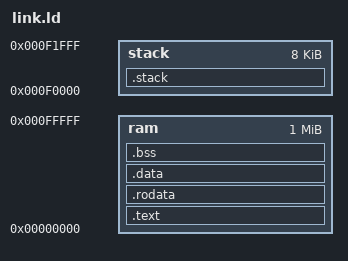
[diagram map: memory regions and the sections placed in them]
/* Copyright lowRISC contributors.
   Licensed under the Apache License, Version 2.0, see LICENSE for details.
   SPDX-License-Identifier: Apache-2.0 */

OUTPUT_ARCH(riscv)

MEMORY
{
    ram         : ORIGIN = 0x00000000, LENGTH = 0x100000 /* 1MB */
    stack       : ORIGIN = 0x000F0000, LENGTH = 0x2000  /* 32 kB */
}

/* Stack information variables */
_min_stack      = 0x2000;   /* 8K - minimum stack space to reserve */
_stack_len     = LENGTH(stack);
_stack_start   = ORIGIN(stack) + LENGTH(stack);

ENTRY(_start)


SECTIONS
{
    .text : {
        . = ALIGN(4);
        *(.text)
        *(.text.*)
    }  > ram

    .rodata : {
        . = ALIGN(4);
        /* Small RO data before large RO data */
        *(.srodata)
        *(.srodata.*)
        *(.rodata);
        *(.rodata.*)
    } > ram

    .data : {
        . = ALIGN(4);
        /* Small data before large data */
        *(.sdata)
        *(.sdata.*)
        *(.data);
        *(.data.*)
    } > ram

    .bss :
    {
        . = ALIGN(4);
        _bss_start = .;
        /* Small BSS before large BSS */
        *(.sbss)
        *(.sbss.*)
        *(.bss)
        *(.bss.*)
        *(COMMON)
        _bss_end = .;
    } > ram

    /* ensure there is enough room for stack */
    .stack (NOLOAD): {
        . = ALIGN(4);
        . = . + _min_stack ;
        . = ALIGN(4);
        stack = . ;
        _stack = . ;
    } > stack
}
